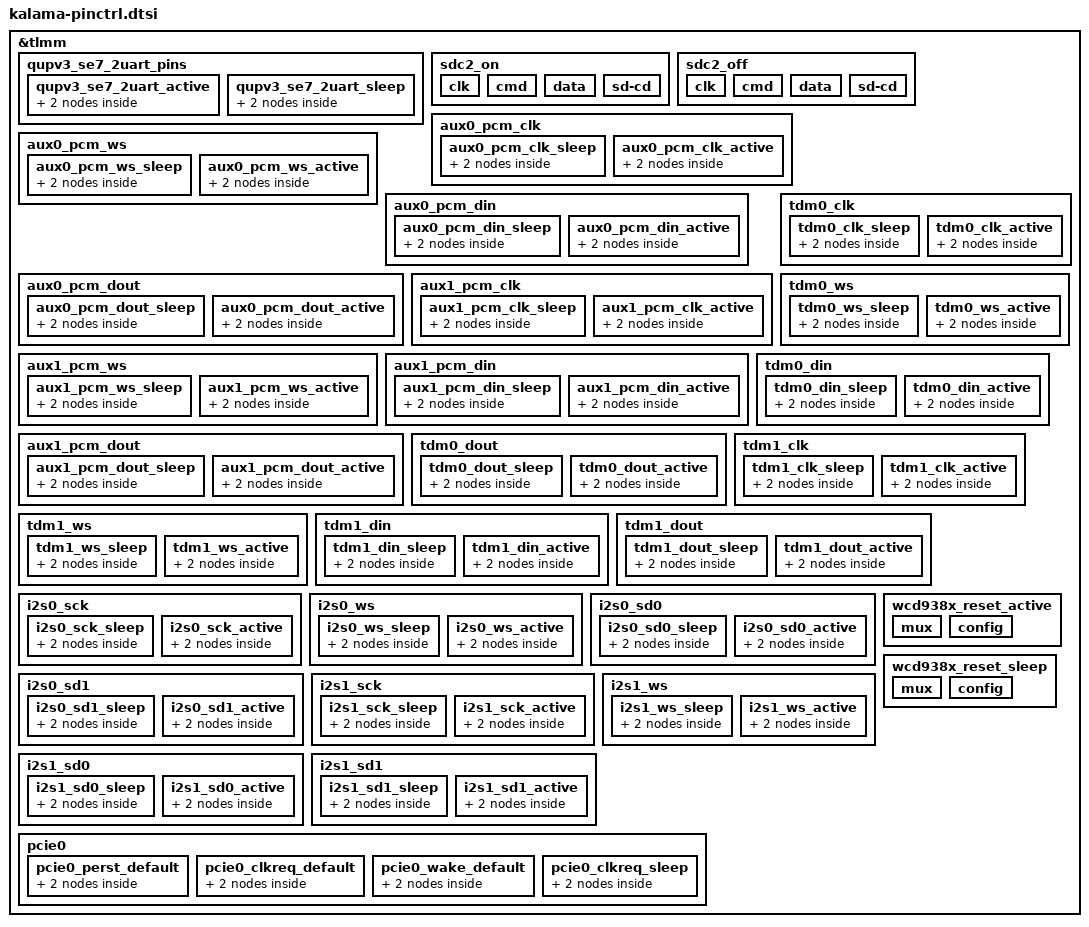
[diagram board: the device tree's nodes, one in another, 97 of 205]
&tlmm {
	qupv3_se7_2uart_pins: qupv3_se7_2uart_pins {
		qupv3_se7_2uart_active: qupv3_se7_2uart_active {
			mux {
				pins = "gpio24", "gpio25";
				function = "qup1_se7";
			};

			config {
				pins = "gpio24", "gpio25";
				drive-strength= <2>;
				bias-disable;
			};
		};

		qupv3_se7_2uart_sleep: qupv3_se7_2uart_sleep {
			mux {
				pins = "gpio24", "gpio25";
				function = "gpio";
			};

			config {
				pins = "gpio24", "gpio25";
				drive-strength = <2>;
				bias-pull-down;
			};
		};
	};

	sdc2_on: sdc2_on {
		clk {
			pins = "sdc2_clk";
			bias-disable;
			drive-strength = <16>;
		};

		cmd {
			pins = "sdc2_cmd";
			bias-pull-up;
			drive-strength = <10>;
		};

		data {
			pins = "sdc2_data";
			bias-pull-up;
			drive-strength = <10>;
		};

		sd-cd {
			pins = "gpio92";
			bias-pull-up;
			drive-strength = <2>;
		};
	};

	sdc2_off: sdc2_off {
		clk {
			pins = "sdc2_clk";
			bias-disable;
			drive-strength = <2>;
		};

		cmd {
			pins = "sdc2_cmd";
			bias-pull-up;
			drive-strength = <2>;
		};

		data {
			pins = "sdc2_data";
			bias-pull-up;
			drive-strength = <2>;
		};

		sd-cd {
			pins = "gpio92";
			bias-pull-up;
			drive-strength = <2>;
		};
	};

	aux0_pcm_clk {
		aux0_pcm_clk_sleep: aux0_pcm_clk_sleep {
			mux {
				pins = "gpio126";
				function = "gpio";
			};

			config {
				pins = "gpio126";
				drive-strength = <2>;   /* 2 mA */
				bias-pull-down;         /* PULL DOWN */
				input-enable;
			};
		};

		aux0_pcm_clk_active: aux0_pcm_clk_active {
			mux {
				pins = "gpio126";
				function = "mi2s0_sck";
			};

			config {
				pins = "gpio126";
				drive-strength = <8>;   /* 8 mA */
				bias-disable;           /* NO PULL */
				output-high;
			};
		};
	};

	aux0_pcm_ws {
		aux0_pcm_ws_sleep: aux0_pcm_ws_sleep {
			mux {
				pins = "gpio129";
				function = "gpio";
			};

			config {
				pins = "gpio129";
				drive-strength = <2>;   /* 2 mA */
				bias-pull-down;         /* PULL DOWN */
				input-enable;
			};
		};

		aux0_pcm_ws_active: aux0_pcm_ws_active {
			mux {
				pins = "gpio129";
				function = "mi2s0_ws";
			};

			config {
				pins = "gpio129";
				drive-strength = <8>;   /* 8 mA */
				bias-disable;           /* NO PULL */
				output-high;
			};
		};
	};

	aux0_pcm_din {
		aux0_pcm_din_sleep: aux0_pcm_din_sleep {
			mux {
				pins = "gpio127";
				function = "gpio";
			};

			config {
				pins = "gpio127";
				drive-strength = <2>;   /* 2 mA */
				bias-pull-down;         /* PULL DOWN */
				input-enable;
			};
		};

		aux0_pcm_din_active: aux0_pcm_din_active {
			mux {
				pins = "gpio127";
				function = "mi2s0_data0";
			};

			config {
				pins = "gpio127";
				drive-strength = <8>;   /* 8 mA */
				bias-disable;           /* NO PULL */
			};
		};
	};

	aux0_pcm_dout {
		aux0_pcm_dout_sleep: aux0_pcm_dout_sleep {
			mux {
				pins = "gpio128";
				function = "gpio";
			};

			config {
				pins = "gpio128";
				drive-strength = <2>;   /* 2 mA */
				bias-pull-down;         /* PULL DOWN */
				input-enable;
			};
		};

		aux0_pcm_dout_active: aux0_pcm_dout_active {
			mux {
				pins = "gpio128";
				function = "mi2s0_data1";
			};

			config {
				pins = "gpio128";
				drive-strength = <8>;   /* 8 mA */
				bias-disable;           /* NO PULL */
			};
		};
	};

	aux1_pcm_clk {
		aux1_pcm_clk_sleep: aux1_pcm_clk_sleep {
			mux {
				pins = "gpio121";
				function = "gpio";
			};

			config {
				pins = "gpio121";
				drive-strength = <2>;   /* 2 mA */
				bias-pull-down;         /* PULL DOWN */
				input-enable;
			};
		};

		aux1_pcm_clk_active: aux1_pcm_clk_active {
			mux {
				pins = "gpio121";
				function = "mi2s2_sck";
			};

			config {
				pins = "gpio121";
				drive-strength = <8>;   /* 8 mA */
				bias-disable;           /* NO PULL */
				output-high;
			};
		};
	};

	aux1_pcm_ws {
		aux1_pcm_ws_sleep: aux1_pcm_ws_sleep {
			mux {
				pins = "gpio123";
				function = "gpio";
			};

			config {
				pins = "gpio123";
				drive-strength = <2>;   /* 2 mA */
				bias-pull-down;         /* PULL DOWN */
				input-enable;
			};
		};

		aux1_pcm_ws_active: aux1_pcm_ws_active {
			mux {
				pins = "gpio123";
				function = "mi2s2_ws";
			};

			config {
				pins = "gpio123";
				drive-strength = <8>;   /* 8 mA */
				bias-disable;           /* NO PULL */
				output-high;
			};
		};
	};

	aux1_pcm_din {
		aux1_pcm_din_sleep: aux1_pcm_din_sleep {
			mux {
				pins = "gpio122";
				function = "gpio";
			};

			config {
				pins = "gpio122";
				drive-strength = <2>;   /* 2 mA */
				bias-pull-down;         /* PULL DOWN */
				input-enable;
			};
		};

		aux1_pcm_din_active: aux1_pcm_din_active {
			mux {
				pins = "gpio122";
				function = "mi2s2_data0";
			};

			config {
				pins = "gpio122";
				drive-strength = <8>;   /* 8 mA */
				bias-disable;           /* NO PULL */
			};
		};
	};

	aux1_pcm_dout {
		aux1_pcm_dout_sleep: aux1_pcm_dout_sleep {
			mux {
				pins = "gpio124";
				function = "gpio";
			};

			config {
				pins = "gpio124";
				drive-strength = <2>;   /* 2 mA */
				bias-pull-down;         /* PULL DOWN */
				input-enable;
			};
		};

		aux1_pcm_dout_active: aux1_pcm_dout_active {
			mux {
				pins = "gpio124";
				function = "mi2s2_data1";
			};

			config {
				pins = "gpio124";
				drive-strength = <8>;   /* 8 mA */
				bias-disable;           /* NO PULL */
			};
		};
	};

	tdm0_clk {
		tdm0_clk_sleep: tdm0_clk_sleep {
			mux {
				pins = "gpio126";
				function = "gpio";
			};

			config {
				pins = "gpio126";
				drive-strength = <2>;   /* 2 mA */
				bias-pull-down;         /* PULL DOWN */
				input-enable;
			};
		};

		tdm0_clk_active: tdm0_clk_active {
			mux {
				pins = "gpio126";
				function = "mi2s0_sck";
			};

			config {
				pins = "gpio126";
				drive-strength = <8>;   /* 8 mA */
				bias-disable;           /* NO PULL */
				output-high;
			};
		};
	};

	tdm0_ws {
		tdm0_ws_sleep: tdm0_ws_sleep {
			mux {
				pins = "gpio129";
				function = "gpio";
			};

			config {
				pins = "gpio129";
				drive-strength = <2>;   /* 2 mA */
				bias-pull-down;         /* PULL DOWN */
				input-enable;
			};
		};

		tdm0_ws_active: tdm0_ws_active {
			mux {
				pins = "gpio129";
				function = "mi2s0_ws";
			};

			config {
				pins = "gpio129";
				drive-strength = <8>;   /* 8 mA */
				bias-disable;           /* NO PULL */
				output-high;
			};
		};
	};

	tdm0_din {
		tdm0_din_sleep: tdm0_din_sleep {
			mux {
				pins = "gpio127";
				function = "gpio";
			};

			config {
				pins = "gpio127";
				drive-strength = <2>;   /* 2 mA */
				bias-pull-down;         /* PULL DOWN */
				input-enable;
			};
		};

		tdm0_din_active: tdm0_din_active {
			mux {
				pins = "gpio127";
				function = "mi2s0_data0";
			};

			config {
				pins = "gpio127";
				drive-strength = <8>;   /* 8 mA */
				bias-disable;           /* NO PULL */
			};
		};
	};

	tdm0_dout {
		tdm0_dout_sleep: tdm0_dout_sleep {
			mux {
				pins = "gpio128";
				function = "gpio";
			};

			config {
				pins = "gpio128";
				drive-strength = <2>;   /* 2 mA */
				bias-pull-down;         /* PULL DOWN */
				input-enable;
			};
		};

		tdm0_dout_active: tdm0_dout_active {
			mux {
				pins = "gpio128";
				function = "mi2s0_data1";
			};

			config {
				pins = "gpio128";
				drive-strength = <8>;   /* 8 mA */
				bias-disable;           /* NO PULL */
			};
		};
	};

	tdm1_clk {
		tdm1_clk_sleep: tdm1_clk_sleep {
			mux {
				pins = "gpio121";
				function = "gpio";
			};

			config {
				pins = "gpio121";
				drive-strength = <2>;   /* 2 mA */
				bias-pull-down;         /* PULL DOWN */
				input-enable;
			};
		};

		tdm1_clk_active: tdm1_clk_active {
			mux {
				pins = "gpio121";
				function = "mi2s2_sck";
			};

			config {
				pins = "gpio121";
				drive-strength = <8>;   /* 8 mA */
				bias-disable;           /* NO PULL */
				output-high;
			};
		};
	};

	tdm1_ws {
		tdm1_ws_sleep: tdm1_ws_sleep {
			mux {
				pins = "gpio123";
				function = "gpio";
			};

			config {
				pins = "gpio123";
				drive-strength = <2>;   /* 2 mA */
				bias-pull-down;         /* PULL DOWN */
				input-enable;
			};
		};

		tdm1_ws_active: tdm1_ws_active {
			mux {
				pins = "gpio123";
				function = "mi2s2_ws";
			};

			config {
				pins = "gpio123";
				drive-strength = <8>;   /* 8 mA */
				bias-disable;           /* NO PULL */
				output-high;
			};
		};
	};

	tdm1_din {
		tdm1_din_sleep: tdm1_din_sleep {
			mux {
				pins = "gpio122";
				function = "gpio";
			};

			config {
				pins = "gpio122";
				drive-strength = <2>;   /* 2 mA */
				bias-pull-down;         /* PULL DOWN */
				input-enable;
			};
		};

		tdm1_din_active: tdm1_din_active {
			mux {
				pins = "gpio122";
				function = "mi2s2_data0";
			};

			config {
				pins = "gpio122";
				drive-strength = <8>;   /* 8 mA */
				bias-disable;           /* NO PULL */
			};
		};
	};

	tdm1_dout {
		tdm1_dout_sleep: tdm1_dout_sleep {
			mux {
				pins = "gpio124";
				function = "gpio";
			};

			config {
				pins = "gpio124";
				drive-strength = <2>;   /* 2 mA */
				bias-pull-down;         /* PULL DOWN */
				input-enable;
			};
		};

		tdm1_dout_active: tdm1_dout_active {
			mux {
				pins = "gpio124";
				function = "mi2s2_data1";
			};

			config {
				pins = "gpio124";
				drive-strength = <8>;   /* 8 mA */
				bias-disable;           /* NO PULL */
			};
		};
	};

	i2s0_sck {
		i2s0_sck_sleep: i2s0_sck_sleep {
			mux {
				pins = "gpio126";
				function = "gpio";
			};

			config {
				pins = "gpio126";
				drive-strength = <2>;   /* 2 mA */
				bias-pull-down;         /* PULL DOWN */
				input-enable;
			};
		};

		i2s0_sck_active: i2s0_sck_active {
			mux {
				pins = "gpio126";
				function = "mi2s0_sck";
			};

			config {
				pins = "gpio126";
				drive-strength = <8>;   /* 8 mA */
				bias-disable;           /* NO PULL */
				output-high;
			};
		};
	};

	i2s0_ws {
		i2s0_ws_sleep: i2s0_ws_sleep {
			mux {
				pins = "gpio129";
				function = "gpio";
			};

			config {
				pins = "gpio129";
				drive-strength = <2>;   /* 2 mA */
				bias-pull-down;         /* PULL DOWN */
				input-enable;
			};
		};

		i2s0_ws_active: i2s0_ws_active {
			mux {
				pins = "gpio129";
				function = "mi2s0_ws";
			};

			config {
				pins = "gpio129";
				drive-strength = <8>;   /* 8 mA */
				bias-disable;           /* NO PULL */
				output-high;
			};
		};
	};

	i2s0_sd0 {
		i2s0_sd0_sleep: i2s0_sd0_sleep {
			mux {
				pins = "gpio127";
				function = "gpio";
			};

			config {
				pins = "gpio127";
				drive-strength = <2>;   /* 2 mA */
				bias-pull-down;         /* PULL DOWN */
				input-enable;
			};
		};

		i2s0_sd0_active: i2s0_sd0_active {
			mux {
				pins = "gpio127";
				function = "mi2s0_data0";
			};

			config {
				pins = "gpio127";
				drive-strength = <8>;   /* 8 mA */
				bias-disable;           /* NO PULL */
				output-high;
			};
		};
	};

	i2s0_sd1 {
		i2s0_sd1_sleep: i2s0_sd1_sleep {
			mux {
				pins = "gpio128";
				function = "gpio";
			};

			config {
				pins = "gpio128";
				drive-strength = <2>;   /* 2 mA */
				bias-pull-down;         /* PULL DOWN */
				input-enable;
			};
		};

		i2s0_sd1_active: i2s0_sd1_active {
			mux {
				pins = "gpio128";
				function = "mi2s0_data1";
			};

			config {
				pins = "gpio128";
				drive-strength = <8>;   /* 8 mA */
				bias-disable;           /* NO PULL */
				output-high;
			};
		};
	};

	i2s1_sck {
		i2s1_sck_sleep: i2s1_sck_sleep {
			mux {
				pins = "gpio121";
				function = "gpio";
			};

			config {
				pins = "gpio121";
				drive-strength = <2>;   /* 2 mA */
				bias-pull-down;         /* PULL DOWN */
				input-enable;
			};
		};

		i2s1_sck_active: i2s1_sck_active {
			mux {
				pins = "gpio121";
				function = "mi2s2_sck";
			};

			config {
				pins = "gpio121";
				drive-strength = <8>;   /* 8 mA */
				bias-disable;           /* NO PULL */
			};
		};
	};

	i2s1_ws {
		i2s1_ws_sleep: i2s1_ws_sleep {
			mux {
				pins = "gpio123";
				function = "gpio";
			};

			config {
				pins = "gpio123";
				drive-strength = <2>;   /* 2 mA */
				bias-pull-down;         /* PULL DOWN */
				input-enable;
			};
		};

		i2s1_ws_active: i2s1_ws_active {
			mux {
				pins = "gpio123";
				function = "mi2s2_ws";
			};

			config {
				pins = "gpio123";
				drive-strength = <8>;   /* 8 mA */
				bias-disable;           /* NO PULL */
			};
		};
	};

	i2s1_sd0 {
		i2s1_sd0_sleep: i2s1_sd0_sleep {
			mux {
				pins = "gpio122";
				function = "gpio";
			};

			config {
				pins = "gpio122";
				drive-strength = <2>;   /* 2 mA */
				bias-pull-down;         /* PULL DOWN */
				input-enable;
			};
		};

		i2s1_sd0_active: i2s1_sd0_active {
			mux {
				pins = "gpio122";
				function = "mi2s2_data0";
			};

			config {
				pins = "gpio122";
				drive-strength = <8>;   /* 8 mA */
				bias-disable;           /* NO PULL */
			};
		};
	};

	i2s1_sd1 {
		i2s1_sd1_sleep: i2s1_sd1_sleep {
			mux {
				pins = "gpio124";
				function = "gpio";
			};

			config {
				pins = "gpio124";
				drive-strength = <2>;   /* 2 mA */
				bias-pull-down;         /* PULL DOWN */
				input-enable;
			};
		};

		i2s1_sd1_active: i2s1_sd1_active {
			mux {
				pins = "gpio124";
				function = "mi2s2_data1";
			};

			config {
				pins = "gpio124";
				drive-strength = <8>;   /* 8 mA */
				bias-disable;           /* NO PULL */
			};
		};
	};

	/* WCD reset pin */
	wcd938x_reset_active: wcd938x_reset_active {
		mux {
			pins = "gpio108";
			function = "gpio";
		};

		config {
			pins = "gpio108";
			drive-strength = <16>;
			output-high;
		};
	};

	wcd938x_reset_sleep: wcd938x_reset_sleep {
		mux {
			pins = "gpio108";
			function = "gpio";
		};

		config {
			pins = "gpio108";
			drive-strength = <16>;
			bias-disable;
			output-low;
		};
	};

	pcie0 {
		pcie0_perst_default: pcie0_perst_default {
			mux {
				pins = "gpio94";
				function = "gpio";
			};

			config {
				pins = "gpio94";
				drive-strength = <2>;
				bias-pull-down;
			};
		};

		pcie0_clkreq_default: pcie0_clkreq_default {
			mux {
				pins = "gpio95";
				function = "pcie0_clkreqn";
			};

			config {
				pins = "gpio95";
				drive-strength = <2>;
				bias-pull-up;
			};
		};

		pcie0_wake_default: pcie0_wake_default {
			mux {
				pins = "gpio96";
				function = "gpio";
			};

			config {
				pins = "gpio96";
				drive-strength = <2>;
				bias-pull-up;
			};
		};

		pcie0_clkreq_sleep: pcie0_clkreq_sleep {
			mux {
				pins = "gpio95";
				function = "gpio";
			};

			config {
				pins = "gpio95";
				drive-strength = <2>;
				bias-pull-up;
			};
		};
	};

};
